# ExynosT100 register map
Vendor: SAMSUNG System LSI; Series: ARMCM4F; File version: 0.1
CPU: CM4 r1p0, little endian, MPU, FPU, 3 interrupt priority bits
Registers are 32-bit, read-write, reset 0x0 unless marked. A register's access mark holds for its fields unless they carry their own. Offsets are from the block's base; [hi:lo] are bit positions; lines under a group give offsets from that group; {n}, {i} and the like mark numbered series; 'fields as' and 'values as' point back to an identical list.

## DMAC — Direct Memory Access Controller Common
Base 0x40002000
0x00 ISR — DMA Interrupt Status Register
  [7:0] Status ro — Status of the DMA interrupts for each channels after masking. (eg. Bit0 indicates the status of channel 0)
0x04 TCISR — DMA Interrupt Terminal Count Status Register
  [7:0] Status ro — Interrupt terminal count request status. (eg. Bit0 indicates the status of channel 0)
0x08 TCICR wo — DMA Interrupt Terminal Count Clear Register
  [7:0] Clear — Terminal count request clear. For each bits, (eg. Bit0 indicates channel 0) 0 = no effect 1 = clear
0x0C EISR ro — DMA Interrupt Error Status Register
  [7:0] IntErrorStatus — Interrupt error status. (eg. Bit0 indicates channel 0)
0x10 EICR — DMA Interrupt Error Clear Register
  [7:0] Clear wo — Interrupt error clear For each bits, (eg. Bit0 indicates channel 0) 0 = no effect 1 = clear
0x14 TCRISR ro — DMA Raw Interrupt Terminal Count Status Register
  [7:0] Status — Status of the terminal count interrupt prior to masking (eg. Bit0 indicates channel 0)
0x18 ERISR ro — DMA Raw Error Interrupt Status Register
  [7:0] Status — Status of the error interrupt prior to masking. (eg. Bit0 indicates channel 0)
0x1C ECR ro — DMA Enabled Channel Register
  [7:0] Enable — Channel enable status (eg. Bit0 indicates channel 0)
0x20 SWBRR — DMA Software Burst Request Register
  [15:0] Request — Software burst request (a DMA request for each source by writing a 1 to the corresponding register bit)
0x24 SWSRR — DMA Software Single Request Register
  [15:0] Request — Software single request
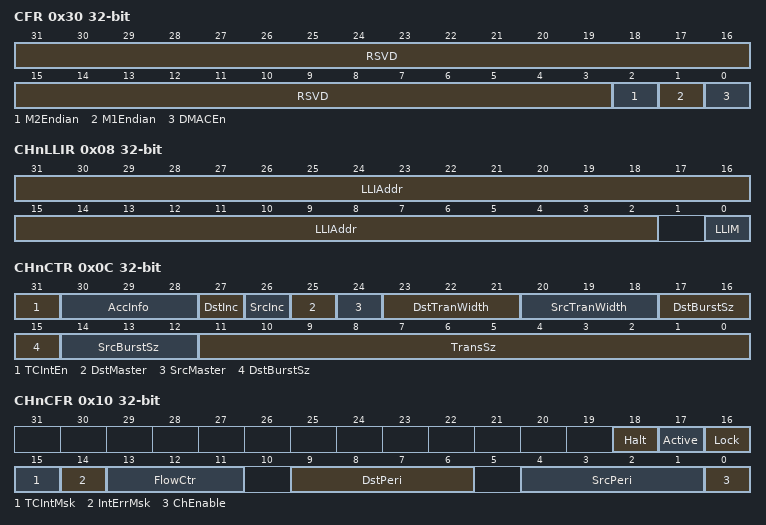
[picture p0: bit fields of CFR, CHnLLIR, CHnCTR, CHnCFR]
0x30 CFR — DMA Configuration Register
  [31:3] RSVD ro
  [2] M2Endian ro — AHB Master 2 endianness configuration: 0 = little-endian mode 1 = big-endian mode. This bit should be 0.
  [1] M1Endian ro — AHB Master 1 endianness configuration: 0 = little-endian mode 1 = big-endian mode. This bit should be 0.
  [0] DMACEn ro — DMAC enable: 0 = disabled 1 = enabled. This bit is reset to 0. Disabling the DMAC reduces power consumption.
0x34 SYR — DMA Synchronization Register
  [15:0] Sync — DMA synchronization logic for DMA request signals enabled or disabled. A LOW bit indicates that the synchronization logic for the request signals is enabled. A HIGH bit indicates that the synchronization logic is disabled. bit set 0 = enable the synchronization logic bit set 1 = disable the synchronization logic
0x100 CH0 group
  0x00 CHnSAR — DMA Channel n Source Address Registers
    [31:0] Addr — DMA source address
  0x04 CHnDAR — DMA Channel n Destination Address Registers
    [31:0] Addr — DMA destination address
  0x08 CHnLLIR — DMA Channel n Linked List Item Registers
    [31:2] LLIAddr — Linked list item. Bits [31:2] of the address for the next LLI ([1:0] are 0).
    [0] LLIM — AHB master select for loading the next LLILM = 0 = AHB Master 1 LM = 1 = AHB Master 2.
  0x0C CHnCTR — DMA Channel n Control Registers
    [31] TCIntEn — Terminal count interrupt enable bit. It controls whether the current LLI is expected to trigger the terminal count interrupt
    [30:28] AccInfo — Protection and access information [30] indicate whether or not the access can be cached 0 = non-cacheable 1 = cacheable [29] indicate whether or not the access can be buffered 0 = non-bufferable 1=bufferable [28] indicate whether the access is in User, or Privileged mode 0 = user mode 1 = privileged mode
    [27] DstInc — Destination increment. When set, the destination address is incremented after each transfer.
    [26] SrcInc — Source increment. When set, the source address is incremented after each transfer.
    [25] DstMaster — Destination AHB master select: 0 = AHB master 1 selected for the destination transfer 1 = AHB master 2 selected for the destination transfer.
    [24] SrcMaster — Source AHB master select: 0 = AHB master 1 selected for the source transfer 1 = AHB master 2 selected for the source transfer.
    [23:21] DstTranWidth — Destination transfer width. The source and destination widths can be different from each other. The hardware automatically packs and unpacks the data when required. 3'b000: Byte (8-bit) 3'b001: Half word (16-bit) 3'b010: Word (32-bit) Others: Reserved
    [20:18] SrcTranWidth — Source transfer width. The source and destination widths can be different from each other. The hardware automatically packs and unpacks the data when required. 3'b000: Byte (8-bit) 3'b001: Half word (16-bit) 3'b010: Word (32-bit) Others: Reserved
    [17:15] DstBurstSz — Destination burst size. Indicates the number of transfers that make up a destination burst transfer request. You must set this value to the burst size of the destination peripheral, or if the destination is memory, to the memory boundary size. The burst size is the amount of data that is transferred when the burst request signal goes active in the destination peripheral. 3'b000: 1 3'b001: 4 3'b010: 8 3'b011: 16 3'b100: 32 3'b101: 64 3'b110: 128 3'b111: 256
    [14:12] SrcBurstSz — Source burst size. Indicates the number of transfers that make up a source burst. You must set this value to the burst size of the source peripheral, or if the source is memory, to the memory boundary size. The burst size is the amount of data that is transferred when the burst request signal goes active in the source peripheral. 3'b000: 1 3'b001: 4 3'b010: 8 3'b011: 16 3'b100: 32 3'b101: 64 3'b110: 128 3'b111: 256
    [11:0] TransSz — RW Transfer size. A write to this field sets the size of the transfer when the DMAC is the flow controller. This value counts down from the original value to zero, and so its value indicates the number of transfers left to complete. A read from this field provides the number of transfers still to be completed on the destination bus. Reading the register when the channel is active does not give useful information because by the time the software has processed the value read, the channel might have progressed. Only use it when a channel is enabled, and then disabled. The ARM PrimeCell DMA Controller (PL080) Design Manual provides more information about the use of this field. Program the transfer size value to zero if the DMAC is not the flow controller. If you program the TransferSize to a non-zero value, the DMAC might attempt to use this value instead of ignoring the TransferSize.
  0x10 CHnCFR — DMA Channel n Configuration Registers
    [18] Halt — Halt: 0 = enable DMA requests 1 = ignore extra source DMA requests. The contents of the channels FIFO are drained. You can use this value with the Active and Channel Enable bits to cleanly disable a DMA channel.
    [17] Active ro — Active: 0 = there is no data in the FIFO of the channel 1 = the FIFO of the channel has data. You can use this value with the Halt and Channel Enable bits to cleanly disable a DMA channel.
    [16] Lock — Lock. When set, this bit enables locked transfers.
    [15] TCIntMsk — Terminal count interrupt mask. When cleared, this bit masks out the terminal count interrupt of the relevant channel.
    [14] IntErrMsk — Interrupt error mask. When cleared, this bit masks out the error interrupt of the relevant channel.
    [13:11] FlowCtr — Flow control and transfer type. 3'b000: memory-to-memory by DMA 3'b001: memory-to-peripheral by DMA 3'b010: peripheral-to-memory by DMA 3'b011: source periphera to destination peripheral by DMA 3'b100: source peripheral to destination peripheral by destination peripheral 3'b101: memory-to-peripheral by peripheral 3'b110: peripheral-to-memory by peripheral 3'b100: source peripheralto destination peripheral by source peripheral
    [9:6] DstPeri — Destination peripheral. This value selects the DMA destination request peripheral. This field is ignored if the destination of the transfer is to memory.
    [4:1] SrcPeri — Source peripheral. This value selects the DMA source request peripheral. This field is ignored if the source of the transfer is from
    [0] ChEnable — Channel enable. Reading this bit indicates whether a channel is currently enabled or disabled: 0 = channel disabled 1 = channel enabled.
{0x100+0x20*i} CH{i} group (i=1..7)
  0x00 CHnSAR — DMA Channel n Source Address Registers
    [31:0] Addr — DMA source address
  0x04 CHnDAR — DMA Channel n Destination Address Registers
    [31:0] Addr — DMA destination address
  0x08 CHnLLIR — DMA Channel n Linked List Item Registers
    fields as CH0.CHnLLIR
  0x0C CHnCTR — DMA Channel n Control Registers
    fields as CH0.CHnCTR
  0x10 CHnCFR — DMA Channel n Configuration Registers
    [18] Halt — Halt: 0 = enable DMA requests 1 = ignore extra source DMA requests. The contents of the channels FIFO are drained. You can use this value with the Active and Channel Enable bits to cleanly disable a DMA channel.
    [17] Active ro — Active: 0 = there is no data in the FIFO of the channel 1 = the FIFO of the channel has data. You can use this value with the Halt and Channel Enable bits to cleanly disable a DMA channel.
    [16] Lock — Lock. When set, this bit enables locked transfers.
    [15] TCIntMsk — Terminal count interrupt mask. When cleared, this bit masks out the terminal count interrupt of the relevant channel.
    [14] IntErrMsk — Interrupt error mask. When cleared, this bit masks out the error interrupt of the relevant channel.
    [13:11] FlowCtr — Flow control and transfer type. 3'b000: memory-to-memory by DMA 3'b001: memory-to-peripheral by DMA 3'b010: peripheral-to-memory by DMA 3'b011: source peripheral to destination peripheral by DMA 3'b100: source peripheral to destination peripheral by destination peripheral 3'b101: memory-to-peripheral by peripheral 3'b110: peripheral-to-memory by peripheral 3'b100: source peripheral to destination peripheral by source peripheral
    [9:6] DstPeri — Destination peripheral. This value selects the DMA destination request peripheral. This field is ignored if the destination of the transfer is to memory.
    [4:1] SrcPeri — Source peripheral. This value selects the DMA source request peripheral. This field is ignored if the source of the transfer is from
    [0] ChEnable — Channel enable. Reading this bit indicates whether a channel is currently enabled or disabled: 0 = channel disabled 1 = channel enabled.
